VERSION ""

NS_ :

BS_:

BU_: CVC FZC RZC SC BCM ICU TCU Tester Plant_Sim

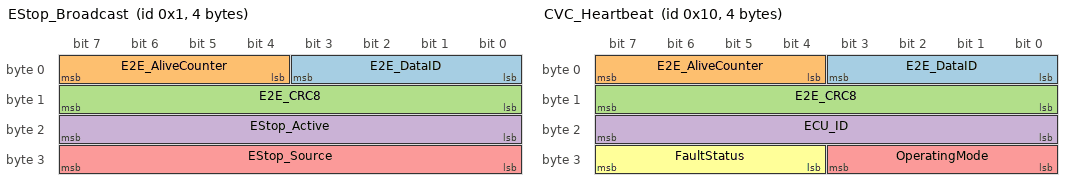
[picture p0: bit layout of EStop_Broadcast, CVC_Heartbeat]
BO_ 1 EStop_Broadcast: 4 CVC
 SG_ E2E_DataID : 0|4@1+ (1,0) [0|15] "" SC,FZC,RZC,BCM,ICU,TCU
 SG_ E2E_AliveCounter : 4|4@1+ (1,0) [0|15] "" SC,FZC,RZC,BCM,ICU,TCU
 SG_ E2E_CRC8 : 8|8@1+ (1,0) [0|255] "" SC,FZC,RZC,BCM,ICU,TCU
 SG_ EStop_Active : 16|8@1+ (1,0) [0|1] "" SC,FZC,RZC,BCM,ICU
 SG_ EStop_Source : 24|8@1+ (1,0) [0|7] "" SC,FZC,RZC,BCM,ICU

BO_ 16 CVC_Heartbeat: 4 CVC
 SG_ E2E_DataID : 0|4@1+ (1,0) [0|15] "" SC,FZC,RZC,ICU
 SG_ E2E_AliveCounter : 4|4@1+ (1,0) [0|15] "" SC,FZC,RZC,ICU
 SG_ E2E_CRC8 : 8|8@1+ (1,0) [0|255] "" SC,FZC,RZC,ICU
 SG_ ECU_ID : 16|8@1+ (1,0) [0|7] "" SC,FZC,RZC,ICU
 SG_ OperatingMode : 24|4@1+ (1,0) [0|5] "" SC,FZC,RZC,ICU
 SG_ FaultStatus : 28|4@1+ (1,0) [0|15] "" SC,FZC,RZC,ICU

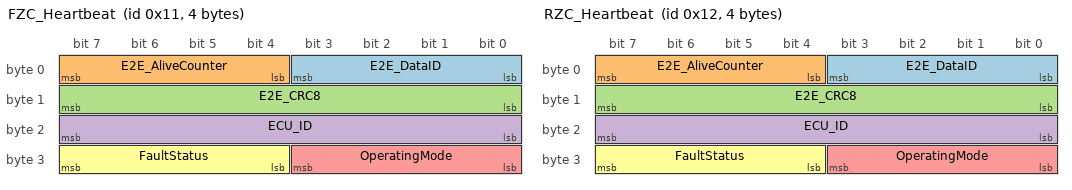
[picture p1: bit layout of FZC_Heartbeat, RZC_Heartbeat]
BO_ 17 FZC_Heartbeat: 4 FZC
 SG_ E2E_DataID : 0|4@1+ (1,0) [0|15] "" SC,CVC,ICU
 SG_ E2E_AliveCounter : 4|4@1+ (1,0) [0|15] "" SC,CVC,ICU
 SG_ E2E_CRC8 : 8|8@1+ (1,0) [0|255] "" SC,CVC,ICU
 SG_ ECU_ID : 16|8@1+ (1,0) [0|7] "" SC,CVC,ICU
 SG_ OperatingMode : 24|4@1+ (1,0) [0|5] "" SC,CVC,ICU
 SG_ FaultStatus : 28|4@1+ (1,0) [0|15] "" SC,CVC,ICU

BO_ 18 RZC_Heartbeat: 4 RZC
 SG_ E2E_DataID : 0|4@1+ (1,0) [0|15] "" SC,CVC,ICU
 SG_ E2E_AliveCounter : 4|4@1+ (1,0) [0|15] "" SC,CVC,ICU
 SG_ E2E_CRC8 : 8|8@1+ (1,0) [0|255] "" SC,CVC,ICU
 SG_ ECU_ID : 16|8@1+ (1,0) [0|7] "" SC,CVC,ICU
 SG_ OperatingMode : 24|4@1+ (1,0) [0|5] "" SC,CVC,ICU
 SG_ FaultStatus : 28|4@1+ (1,0) [0|15] "" SC,CVC,ICU

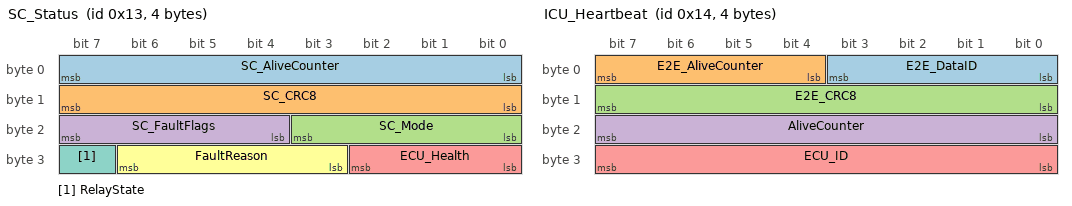
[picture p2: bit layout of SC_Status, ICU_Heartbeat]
BO_ 19 SC_Status: 4 SC
 SG_ SC_AliveCounter : 0|8@1+ (1,0) [0|255] "" CVC,FZC,RZC,ICU
 SG_ SC_CRC8 : 8|8@1+ (1,0) [0|255] "" CVC,FZC,RZC,ICU
 SG_ SC_Mode : 16|4@1+ (1,0) [0|3] "" CVC,FZC,RZC,ICU
 SG_ SC_FaultFlags : 20|4@1+ (1,0) [0|15] "" CVC,FZC,RZC,ICU
 SG_ ECU_Health : 24|3@1+ (1,0) [0|7] "" CVC,FZC,RZC,ICU
 SG_ FaultReason : 27|4@1+ (1,0) [0|15] "" CVC,FZC,RZC,ICU
 SG_ RelayState : 31|1@1+ (1,0) [0|1] "" CVC,FZC,RZC,ICU

BO_ 20 ICU_Heartbeat: 4 ICU
 SG_ E2E_DataID : 0|4@1+ (1,0) [0|15] "" CVC
 SG_ E2E_AliveCounter : 4|4@1+ (1,0) [0|15] "" CVC
 SG_ E2E_CRC8 : 8|8@1+ (1,0) [0|255] "" CVC
 SG_ AliveCounter : 16|8@1+ (1,0) [0|255] "" CVC
 SG_ ECU_ID : 24|8@1+ (1,0) [0|7] "" CVC

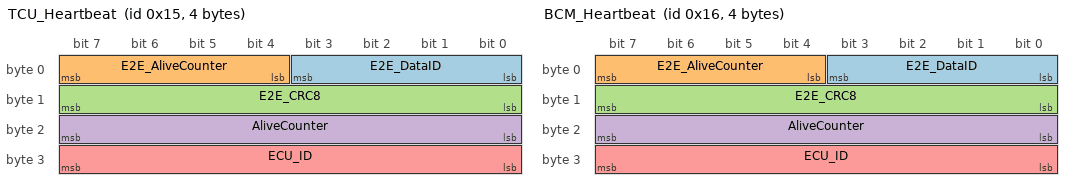
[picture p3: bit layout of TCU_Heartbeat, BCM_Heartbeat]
BO_ 21 TCU_Heartbeat: 4 TCU
 SG_ E2E_DataID : 0|4@1+ (1,0) [0|15] "" CVC
 SG_ E2E_AliveCounter : 4|4@1+ (1,0) [0|15] "" CVC
 SG_ E2E_CRC8 : 8|8@1+ (1,0) [0|255] "" CVC
 SG_ AliveCounter : 16|8@1+ (1,0) [0|255] "" CVC
 SG_ ECU_ID : 24|8@1+ (1,0) [0|7] "" CVC

BO_ 22 BCM_Heartbeat: 4 BCM
 SG_ E2E_DataID : 0|4@1+ (1,0) [0|15] "" CVC,ICU
 SG_ E2E_AliveCounter : 4|4@1+ (1,0) [0|15] "" CVC,ICU
 SG_ E2E_CRC8 : 8|8@1+ (1,0) [0|255] "" CVC,ICU
 SG_ AliveCounter : 16|8@1+ (1,0) [0|255] "" CVC,ICU
 SG_ ECU_ID : 24|8@1+ (1,0) [0|7] "" CVC,ICU

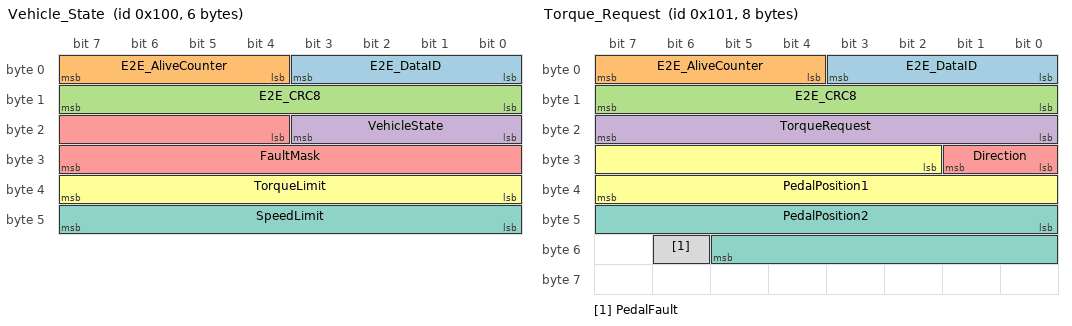
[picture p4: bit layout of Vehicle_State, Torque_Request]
BO_ 256 Vehicle_State: 6 CVC
 SG_ E2E_DataID : 0|4@1+ (1,0) [0|15] "" FZC,RZC,BCM,ICU,SC
 SG_ E2E_AliveCounter : 4|4@1+ (1,0) [0|15] "" FZC,RZC,BCM,ICU,SC
 SG_ E2E_CRC8 : 8|8@1+ (1,0) [0|255] "" FZC,RZC,BCM,ICU,SC
 SG_ VehicleState : 16|4@1+ (1,0) [0|5] "" FZC,RZC,BCM,ICU,SC
 SG_ FaultMask : 20|12@1+ (1,0) [0|4095] "" FZC,RZC,BCM,ICU,SC
 SG_ TorqueLimit : 32|8@1+ (1,0) [0|100] "%" RZC,ICU
 SG_ SpeedLimit : 40|8@1+ (1,0) [0|100] "%" RZC,ICU

BO_ 257 Torque_Request: 8 CVC
 SG_ E2E_DataID : 0|4@1+ (1,0) [0|15] "" RZC
 SG_ E2E_AliveCounter : 4|4@1+ (1,0) [0|15] "" RZC
 SG_ E2E_CRC8 : 8|8@1+ (1,0) [0|255] "" RZC
 SG_ TorqueRequest : 16|8@1+ (1,0) [0|100] "%" RZC
 SG_ Direction : 24|2@1+ (1,0) [0|2] "" RZC
 SG_ PedalPosition1 : 26|14@1+ (0.022,0) [0|359.98] "deg" RZC
 SG_ PedalPosition2 : 40|14@1+ (0.022,0) [0|359.98] "deg" RZC
 SG_ PedalFault : 54|1@1+ (1,0) [0|1] "" RZC

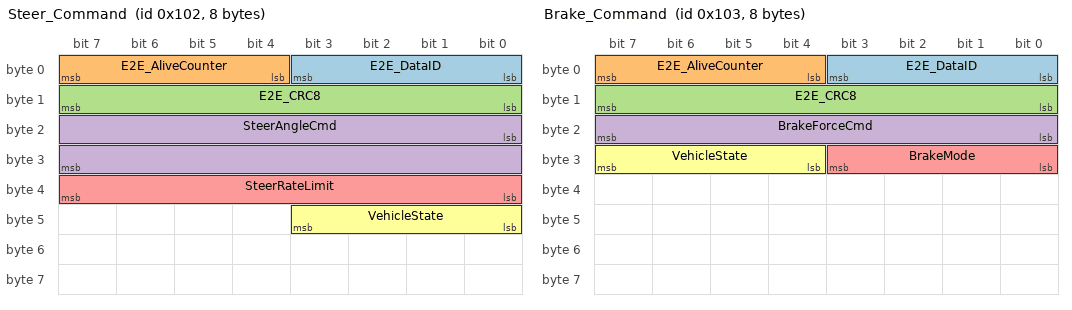
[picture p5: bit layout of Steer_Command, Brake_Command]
BO_ 258 Steer_Command: 8 CVC
 SG_ E2E_DataID : 0|4@1+ (1,0) [0|15] "" FZC
 SG_ E2E_AliveCounter : 4|4@1+ (1,0) [0|15] "" FZC
 SG_ E2E_CRC8 : 8|8@1+ (1,0) [0|255] "" FZC
 SG_ SteerAngleCmd : 16|16@1- (0.01,0) [-45.0|45.0] "deg" FZC
 SG_ SteerRateLimit : 32|8@1+ (0.2,0) [0|51.0] "deg/s" FZC
 SG_ VehicleState : 40|4@1+ (1,0) [0|5] "" FZC

BO_ 259 Brake_Command: 8 CVC
 SG_ E2E_DataID : 0|4@1+ (1,0) [0|15] "" FZC
 SG_ E2E_AliveCounter : 4|4@1+ (1,0) [0|15] "" FZC
 SG_ E2E_CRC8 : 8|8@1+ (1,0) [0|255] "" FZC
 SG_ BrakeForceCmd : 16|8@1+ (1,0) [0|100] "%" FZC
 SG_ BrakeMode : 24|4@1+ (1,0) [0|3] "" FZC
 SG_ VehicleState : 28|4@1+ (1,0) [0|5] "" FZC

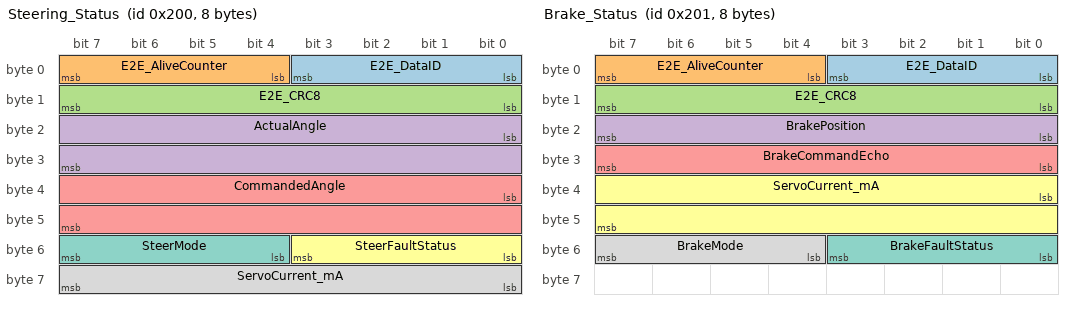
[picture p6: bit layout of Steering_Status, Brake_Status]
BO_ 512 Steering_Status: 8 FZC
 SG_ E2E_DataID : 0|4@1+ (1,0) [0|15] "" CVC,SC,ICU
 SG_ E2E_AliveCounter : 4|4@1+ (1,0) [0|15] "" CVC,SC,ICU
 SG_ E2E_CRC8 : 8|8@1+ (1,0) [0|255] "" CVC,SC,ICU
 SG_ ActualAngle : 16|16@1- (1,0) [-45|45] "deg" CVC,SC,ICU
 SG_ CommandedAngle : 32|16@1- (1,0) [-45|45] "deg" CVC,SC,ICU
 SG_ SteerFaultStatus : 48|4@1+ (1,0) [0|15] "" CVC,SC,ICU
 SG_ SteerMode : 52|4@1+ (1,0) [0|3] "" CVC,SC,ICU
 SG_ ServoCurrent_mA : 56|8@1+ (10,0) [0|2550] "mA" CVC,SC,ICU

BO_ 513 Brake_Status: 8 FZC
 SG_ E2E_DataID : 0|4@1+ (1,0) [0|15] "" CVC,SC,ICU
 SG_ E2E_AliveCounter : 4|4@1+ (1,0) [0|15] "" CVC,SC,ICU
 SG_ E2E_CRC8 : 8|8@1+ (1,0) [0|255] "" CVC,SC,ICU
 SG_ BrakePosition : 16|8@1+ (1,0) [0|100] "%" CVC,SC,ICU
 SG_ BrakeCommandEcho : 24|8@1+ (1,0) [0|100] "%" CVC,SC,ICU
 SG_ ServoCurrent_mA : 32|16@1+ (1,0) [0|3000] "mA" CVC,SC,ICU
 SG_ BrakeFaultStatus : 48|4@1+ (1,0) [0|15] "" CVC,SC,ICU
 SG_ BrakeMode : 52|4@1+ (1,0) [0|3] "" CVC,SC,ICU

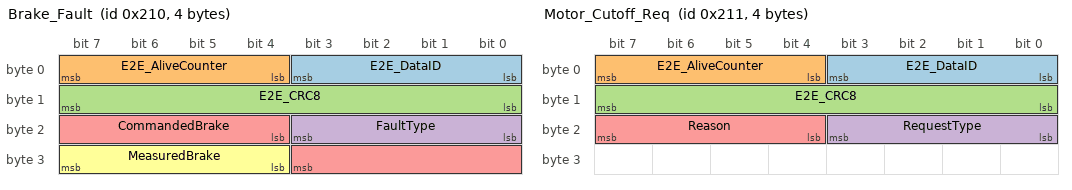
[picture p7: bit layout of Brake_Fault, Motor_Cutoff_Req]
BO_ 528 Brake_Fault: 4 FZC
 SG_ E2E_DataID : 0|4@1+ (1,0) [0|15] "" CVC,SC
 SG_ E2E_AliveCounter : 4|4@1+ (1,0) [0|15] "" CVC,SC
 SG_ E2E_CRC8 : 8|8@1+ (1,0) [0|255] "" CVC,SC
 SG_ FaultType : 16|4@1+ (1,0) [0|3] "" CVC,SC
 SG_ CommandedBrake : 20|8@1+ (1,0) [0|100] "%" CVC,SC
 SG_ MeasuredBrake : 28|4@1+ (10,0) [0|100] "%" CVC,SC

BO_ 529 Motor_Cutoff_Req: 4 FZC
 SG_ E2E_DataID : 0|4@1+ (1,0) [0|15] "" CVC
 SG_ E2E_AliveCounter : 4|4@1+ (1,0) [0|15] "" CVC
 SG_ E2E_CRC8 : 8|8@1+ (1,0) [0|255] "" CVC
 SG_ RequestType : 16|4@1+ (1,0) [0|3] "" CVC
 SG_ Reason : 20|4@1+ (1,0) [0|7] "" CVC

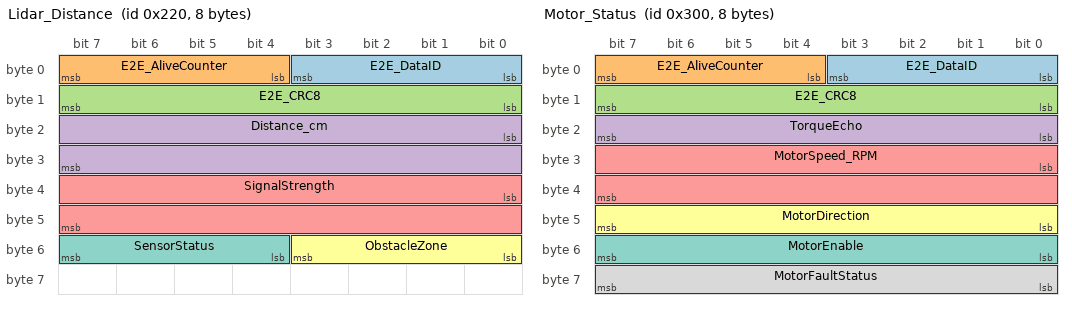
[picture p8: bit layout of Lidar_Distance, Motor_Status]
BO_ 544 Lidar_Distance: 8 FZC
 SG_ E2E_DataID : 0|4@1+ (1,0) [0|15] "" CVC,ICU
 SG_ E2E_AliveCounter : 4|4@1+ (1,0) [0|15] "" CVC,ICU
 SG_ E2E_CRC8 : 8|8@1+ (1,0) [0|255] "" CVC,ICU
 SG_ Distance_cm : 16|16@1+ (1,0) [0|1200] "cm" CVC,ICU
 SG_ SignalStrength : 32|16@1+ (1,0) [0|65535] "" CVC,ICU
 SG_ ObstacleZone : 48|4@1+ (1,0) [0|3] "" CVC,ICU
 SG_ SensorStatus : 52|4@1+ (1,0) [0|15] "" CVC,ICU

BO_ 768 Motor_Status: 8 RZC
 SG_ E2E_DataID : 0|4@1+ (1,0) [0|15] "" CVC,SC,ICU
 SG_ E2E_AliveCounter : 4|4@1+ (1,0) [0|15] "" CVC,SC,ICU
 SG_ E2E_CRC8 : 8|8@1+ (1,0) [0|255] "" CVC,SC,ICU
 SG_ TorqueEcho : 16|8@1+ (1,0) [0|100] "%" CVC,SC,ICU
 SG_ MotorSpeed_RPM : 24|16@1+ (1,0) [0|10000] "RPM" CVC,SC,ICU
 SG_ MotorDirection : 40|8@1+ (1,0) [0|2] "" CVC,SC,ICU
 SG_ MotorEnable : 48|8@1+ (1,0) [0|1] "" CVC,SC,ICU
 SG_ MotorFaultStatus : 56|8@1+ (1,0) [0|31] "" CVC,SC,ICU

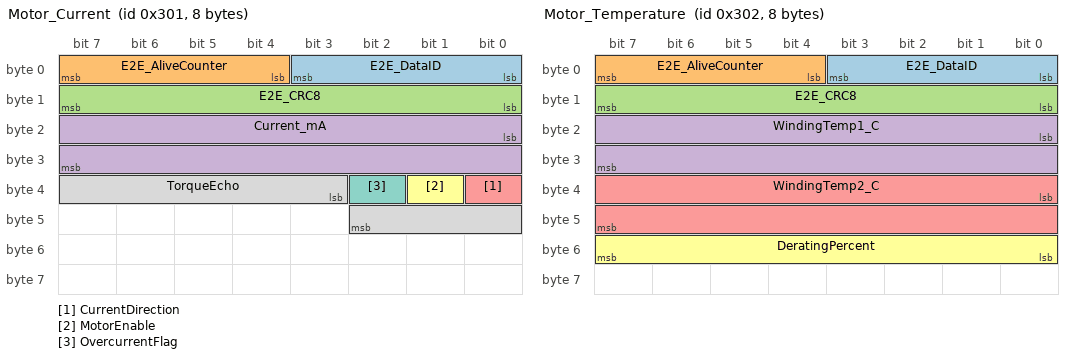
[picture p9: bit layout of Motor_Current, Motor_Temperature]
BO_ 769 Motor_Current: 8 RZC
 SG_ E2E_DataID : 0|4@1+ (1,0) [0|15] "" SC,CVC,ICU
 SG_ E2E_AliveCounter : 4|4@1+ (1,0) [0|15] "" SC,CVC,ICU
 SG_ E2E_CRC8 : 8|8@1+ (1,0) [0|255] "" SC,CVC,ICU
 SG_ Current_mA : 16|16@1+ (1,0) [0|30000] "mA" SC,CVC,ICU
 SG_ CurrentDirection : 32|1@1+ (1,0) [0|1] "" SC,CVC,ICU
 SG_ MotorEnable : 33|1@1+ (1,0) [0|1] "" SC,CVC,ICU
 SG_ OvercurrentFlag : 34|1@1+ (1,0) [0|1] "" SC,CVC,ICU
 SG_ TorqueEcho : 35|8@1+ (1,0) [0|100] "%" SC,CVC,ICU

BO_ 770 Motor_Temperature: 8 RZC
 SG_ E2E_DataID : 0|4@1+ (1,0) [0|15] "" CVC,ICU
 SG_ E2E_AliveCounter : 4|4@1+ (1,0) [0|15] "" CVC,ICU
 SG_ E2E_CRC8 : 8|8@1+ (1,0) [0|255] "" CVC,ICU
 SG_ WindingTemp1_C : 16|16@1+ (0.1,0) [0|200.0] "degC" CVC,ICU
 SG_ WindingTemp2_C : 32|16@1+ (0.1,0) [0|200.0] "degC" CVC,ICU
 SG_ DeratingPercent : 48|8@1+ (1,0) [0|100] "%" CVC,ICU

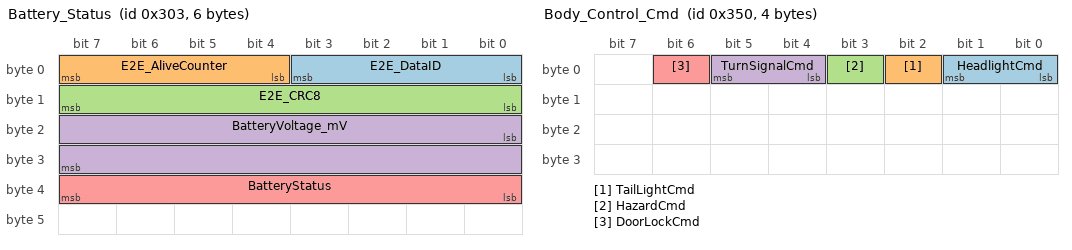
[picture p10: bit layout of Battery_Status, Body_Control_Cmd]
BO_ 771 Battery_Status: 6 RZC
 SG_ E2E_DataID : 0|4@1+ (1,0) [0|15] "" CVC,ICU
 SG_ E2E_AliveCounter : 4|4@1+ (1,0) [0|15] "" CVC,ICU
 SG_ E2E_CRC8 : 8|8@1+ (1,0) [0|255] "" CVC,ICU
 SG_ BatteryVoltage_mV : 16|16@1+ (1,0) [0|20000] "mV" CVC,ICU
 SG_ BatteryStatus : 32|8@1+ (1,0) [0|4] "" CVC,ICU

BO_ 848 Body_Control_Cmd: 4 CVC
 SG_ HeadlightCmd : 0|2@1+ (1,0) [0|2] "" BCM
 SG_ TailLightCmd : 2|1@1+ (1,0) [0|1] "" BCM
 SG_ HazardCmd : 3|1@1+ (1,0) [0|1] "" BCM
 SG_ TurnSignalCmd : 4|2@1+ (1,0) [0|2] "" BCM
 SG_ DoorLockCmd : 6|1@1+ (1,0) [0|1] "" BCM

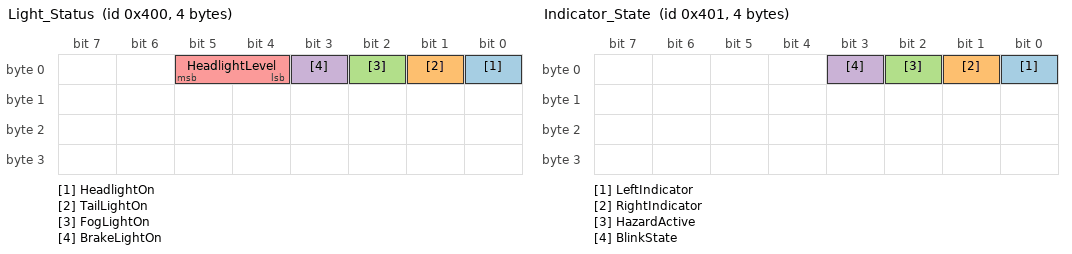
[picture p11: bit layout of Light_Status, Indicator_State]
BO_ 1024 Light_Status: 4 BCM
 SG_ HeadlightOn : 0|1@1+ (1,0) [0|1] "" ICU
 SG_ TailLightOn : 1|1@1+ (1,0) [0|1] "" ICU
 SG_ FogLightOn : 2|1@1+ (1,0) [0|1] "" ICU
 SG_ BrakeLightOn : 3|1@1+ (1,0) [0|1] "" ICU
 SG_ HeadlightLevel : 4|2@1+ (1,0) [0|2] "" ICU

BO_ 1025 Indicator_State: 4 BCM
 SG_ LeftIndicator : 0|1@1+ (1,0) [0|1] "" ICU
 SG_ RightIndicator : 1|1@1+ (1,0) [0|1] "" ICU
 SG_ HazardActive : 2|1@1+ (1,0) [0|1] "" ICU
 SG_ BlinkState : 3|1@1+ (1,0) [0|1] "" ICU

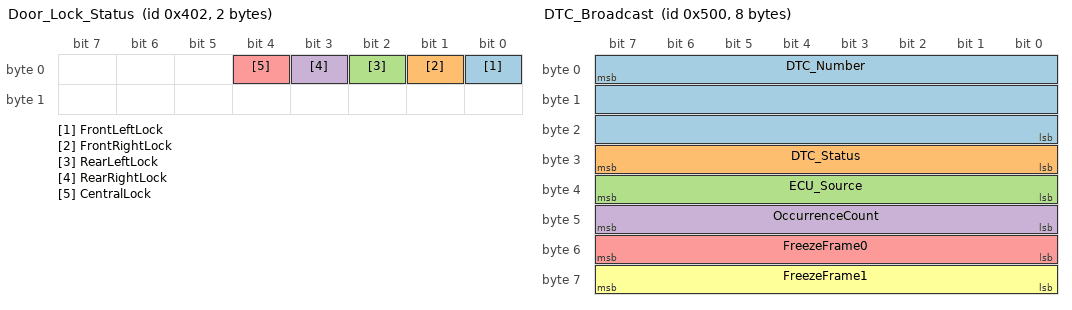
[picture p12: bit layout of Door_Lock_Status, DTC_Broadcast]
BO_ 1026 Door_Lock_Status: 2 BCM
 SG_ FrontLeftLock : 0|1@1+ (1,0) [0|1] "" ICU
 SG_ FrontRightLock : 1|1@1+ (1,0) [0|1] "" ICU
 SG_ RearLeftLock : 2|1@1+ (1,0) [0|1] "" ICU
 SG_ RearRightLock : 3|1@1+ (1,0) [0|1] "" ICU
 SG_ CentralLock : 4|1@1+ (1,0) [0|1] "" ICU

BO_ 1280 DTC_Broadcast: 8 CVC
 SG_ DTC_Number : 7|24@0+ (1,0) [0|16777215] "" TCU,ICU
 SG_ DTC_Status : 24|8@1+ (1,0) [0|255] "" TCU,ICU
 SG_ ECU_Source : 32|8@1+ (1,0) [0|7] "" TCU,ICU
 SG_ OccurrenceCount : 40|8@1+ (1,0) [0|255] "" TCU,ICU
 SG_ FreezeFrame0 : 48|8@1+ (1,0) [0|255] "" TCU,ICU
 SG_ FreezeFrame1 : 56|8@1+ (1,0) [0|255] "" TCU,ICU

BO_ 2015 UDS_Func_Request: 8 Tester
 SG_ UDS_Data : 0|64@1+ (1,0) [0|0] "" CVC,FZC,RZC,TCU,BCM,ICU

BO_ 2016 UDS_Phys_Req_CVC: 8 Tester
 SG_ UDS_Data : 0|64@1+ (1,0) [0|0] "" CVC

BO_ 2017 UDS_Phys_Req_FZC: 8 Tester
 SG_ UDS_Data : 0|64@1+ (1,0) [0|0] "" FZC

BO_ 2018 UDS_Phys_Req_RZC: 8 Tester
 SG_ UDS_Data : 0|64@1+ (1,0) [0|0] "" RZC

BO_ 2019 UDS_Phys_Req_TCU: 8 Tester
 SG_ UDS_Data : 0|64@1+ (1,0) [0|0] "" TCU

BO_ 2024 UDS_Resp_CVC: 8 CVC
 SG_ UDS_Data : 0|64@1+ (1,0) [0|0] "" Tester

BO_ 2025 UDS_Resp_FZC: 8 FZC
 SG_ UDS_Data : 0|64@1+ (1,0) [0|0] "" Tester

BO_ 2026 UDS_Resp_RZC: 8 RZC
 SG_ UDS_Data : 0|64@1+ (1,0) [0|0] "" Tester

BO_ 1604 UDS_Resp_TCU: 8 TCU
 SG_ UDS_Data : 0|64@1+ (1,0) [0|0] "" Tester

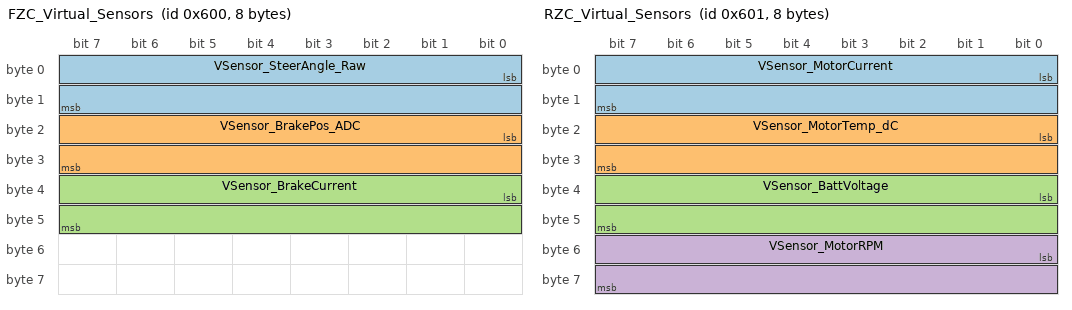
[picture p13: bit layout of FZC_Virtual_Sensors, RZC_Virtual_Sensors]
BO_ 1536 FZC_Virtual_Sensors: 8 Plant_Sim
 SG_ VSensor_SteerAngle_Raw : 0|16@1+ (1,0) [0|16383] "" FZC
 SG_ VSensor_BrakePos_ADC : 16|16@1+ (1,0) [0|1000] "" FZC
 SG_ VSensor_BrakeCurrent : 32|16@1+ (1,0) [0|65535] "mA" FZC

BO_ 1537 RZC_Virtual_Sensors: 8 Plant_Sim
 SG_ VSensor_MotorCurrent : 0|16@1+ (1,0) [0|65535] "mA" RZC
 SG_ VSensor_MotorTemp_dC : 16|16@1+ (1,0) [0|2000] "" RZC
 SG_ VSensor_BattVoltage : 32|16@1+ (1,0) [0|20000] "mV" RZC
 SG_ VSensor_MotorRPM : 48|16@1+ (1,0) [0|10000] "rpm" RZC

CM_ BO_ 1536 "Plant-sim virtual sensors for FZC. SIL/HIL only. 10ms periodic. No E2E.";
CM_ BO_ 1537 "Plant-sim virtual sensors for RZC. SIL/HIL only. 10ms periodic. No E2E.";

CM_ BU_ CVC "Central Vehicle Computer -- STM32F446RE, ASIL D";
CM_ BU_ FZC "Front Zone Controller -- STM32F446RE, ASIL D";
CM_ BU_ RZC "Rear Zone Controller -- STM32F446RE, ASIL C";
CM_ BU_ SC "Safety Controller -- TMS570LS0432, ASIL D";
CM_ BU_ BCM "Body Control Module -- Docker simulated, QM";
CM_ BU_ ICU "Instrument Cluster Unit -- Docker simulated, QM";
CM_ BU_ TCU "Telematics Control Unit -- Docker simulated, QM";

CM_ BO_ 1 "Emergency stop broadcast. Event-triggered, 10ms repeat while active.";
CM_ BO_ 16 "CVC heartbeat. 50ms periodic. SC monitors for timeout.";
CM_ BO_ 17 "FZC heartbeat. 50ms periodic. SC monitors for timeout.";
CM_ BO_ 18 "RZC heartbeat. 50ms periodic. SC monitors for timeout.";
CM_ BO_ 19 "SC status broadcast. 500ms periodic. Simplified E2E (8-bit counter + CRC-8).";
CM_ BO_ 20 "ICU heartbeat. 500ms periodic. QM.";
CM_ BO_ 21 "TCU heartbeat. 500ms periodic. QM.";
CM_ BO_ 256 "Vehicle state broadcast. 10ms periodic. Contains state machine and torque/speed limits.";
CM_ BO_ 257 "Torque request from CVC to RZC. 10ms periodic. ASIL D.";
CM_ BO_ 258 "Steering command from CVC to FZC. 10ms periodic. ASIL D.";
CM_ BO_ 259 "Brake command from CVC to FZC. 10ms periodic. ASIL D.";
CM_ BO_ 512 "Steering status feedback from FZC. 20ms periodic.";
CM_ BO_ 513 "Brake status feedback from FZC. 20ms periodic.";
CM_ BO_ 528 "Brake fault event from FZC. ASIL D.";
CM_ BO_ 529 "Motor cutoff request from FZC to CVC. Event, 10ms repeat.";
CM_ BO_ 544 "Lidar distance from FZC. 10ms periodic. TFMini-S sensor.";
CM_ BO_ 768 "Motor status from RZC. 20ms periodic. Encoder speed + faults.";
CM_ BO_ 769 "Motor current from RZC. 10ms periodic. ACS723 sensor.";
CM_ BO_ 770 "Motor temperature from RZC. 100ms periodic. NTC thermistor.";
CM_ BO_ 771 "Battery status from RZC. 1000ms periodic. No E2E.";
CM_ BO_ 848 "Body control command from CVC to BCM. 100ms periodic.";
CM_ BO_ 1024 "Light status from BCM. 100ms periodic.";
CM_ BO_ 1025 "Indicator state from BCM. 100ms periodic.";
CM_ BO_ 1026 "Door lock status from BCM. Event-triggered.";
CM_ BO_ 1280 "DTC broadcast. Event-triggered. Any ECU can send.";

VAL_ 1 EStop_Source 0 "CVC_button" 1 "CAN_request" 2 "SC_relay" ;
VAL_ 16 OperatingMode 0 "INIT" 1 "RUN" 2 "DEGRADED" 3 "LIMP" 4 "SAFE_STOP" 5 "SHUTDOWN" ;
VAL_ 17 OperatingMode 0 "INIT" 1 "RUN" 2 "DEGRADED" 3 "LIMP" 4 "SAFE_STOP" 5 "SHUTDOWN" ;
VAL_ 18 OperatingMode 0 "INIT" 1 "RUN" 2 "DEGRADED" 3 "LIMP" 4 "SAFE_STOP" 5 "SHUTDOWN" ;
VAL_ 19 SC_Mode 0 "INIT" 1 "MONITORING" 2 "FAULT_DETECTED" 3 "SAFE_STOP" ;
VAL_ 256 VehicleState 0 "INIT" 1 "RUN" 2 "DEGRADED" 3 "LIMP" 4 "SAFE_STOP" 5 "SHUTDOWN" ;
VAL_ 257 Direction 0 "stopped" 1 "forward" 2 "reverse" ;
VAL_ 259 BrakeMode 0 "release" 1 "normal" 2 "emergency" 3 "auto" ;
VAL_ 512 SteerMode 0 "normal" 1 "return_center" 2 "disabled" 3 "local" ;
VAL_ 513 BrakeMode 0 "release" 1 "normal" 2 "auto_brake" 3 "emergency" ;
VAL_ 528 FaultType 0 "PWM_mismatch" 1 "servo_stuck" 2 "overcurrent" 3 "timeout" ;
VAL_ 529 RequestType 0 "motor_cutoff" 1 "speed_reduce" 2 "e_stop_fwd" ;
VAL_ 529 Reason 0 "brake_fault" 1 "steer_fault" 2 "lidar_emergency" 3 "CAN_loss" ;
VAL_ 544 ObstacleZone 0 "emergency" 1 "braking" 2 "warning" 3 "clear" ;
VAL_ 768 MotorDirection 0 "stopped" 1 "forward" 2 "reverse" ;
VAL_ 769 CurrentDirection 0 "forward" 1 "reverse" ;
VAL_ 771 BatteryStatus 0 "critical_UV" 1 "UV_warn" 2 "normal" 3 "OV_warn" 4 "critical_OV" ;
VAL_ 848 HeadlightCmd 0 "off" 1 "low" 2 "high" ;
VAL_ 848 TurnSignalCmd 0 "off" 1 "left" 2 "right" ;
VAL_ 1024 HeadlightLevel 0 "off" 1 "low" 2 "high" ;
VAL_ 1280 ECU_Source 1 "CVC" 2 "FZC" 3 "RZC" 4 "SC" 5 "BCM" 6 "ICU" 7 "TCU" ;

BA_DEF_ BO_ "GenMsgCycleTime" INT 0 10000;
BA_DEF_ BO_ "GenMsgSendType" STRING;
BA_DEF_ BO_ "ASIL" STRING;
BA_DEF_ BO_ "E2E_DataID" INT -1 255;

BA_ "GenMsgCycleTime" BO_ 1 10;
BA_ "GenMsgCycleTime" BO_ 16 50;
BA_ "GenMsgCycleTime" BO_ 17 50;
BA_ "GenMsgCycleTime" BO_ 18 50;
BA_ "GenMsgCycleTime" BO_ 19 500;
BA_ "GenMsgCycleTime" BO_ 20 500;
BA_ "GenMsgCycleTime" BO_ 21 500;
BA_ "GenMsgCycleTime" BO_ 256 10;
BA_ "GenMsgCycleTime" BO_ 257 10;
BA_ "GenMsgCycleTime" BO_ 258 10;
BA_ "GenMsgCycleTime" BO_ 259 10;
BA_ "GenMsgCycleTime" BO_ 512 20;
BA_ "GenMsgCycleTime" BO_ 513 20;
BA_ "GenMsgCycleTime" BO_ 528 0;
BA_ "GenMsgCycleTime" BO_ 529 10;
BA_ "GenMsgCycleTime" BO_ 544 10;
BA_ "GenMsgCycleTime" BO_ 768 20;
BA_ "GenMsgCycleTime" BO_ 769 10;
BA_ "GenMsgCycleTime" BO_ 770 100;
BA_ "GenMsgCycleTime" BO_ 771 1000;
BA_ "GenMsgCycleTime" BO_ 848 100;
BA_ "GenMsgCycleTime" BO_ 1024 100;
BA_ "GenMsgCycleTime" BO_ 1025 100;
BA_ "GenMsgCycleTime" BO_ 1026 0;
BA_ "GenMsgCycleTime" BO_ 1280 0;

BA_ "GenMsgSendType" BO_ 1 "event";
BA_ "GenMsgSendType" BO_ 16 "cyclic";
BA_ "GenMsgSendType" BO_ 17 "cyclic";
BA_ "GenMsgSendType" BO_ 18 "cyclic";
BA_ "GenMsgSendType" BO_ 19 "cyclic";
BA_ "GenMsgSendType" BO_ 20 "cyclic";
BA_ "GenMsgSendType" BO_ 21 "cyclic";
BA_ "GenMsgSendType" BO_ 256 "cyclic";
BA_ "GenMsgSendType" BO_ 257 "cyclic";
BA_ "GenMsgSendType" BO_ 258 "cyclic";
BA_ "GenMsgSendType" BO_ 259 "cyclic";
BA_ "GenMsgSendType" BO_ 512 "cyclic";
BA_ "GenMsgSendType" BO_ 513 "cyclic";
BA_ "GenMsgSendType" BO_ 528 "event";
BA_ "GenMsgSendType" BO_ 529 "event";
BA_ "GenMsgSendType" BO_ 544 "cyclic";
BA_ "GenMsgSendType" BO_ 768 "cyclic";
BA_ "GenMsgSendType" BO_ 769 "cyclic";
BA_ "GenMsgSendType" BO_ 770 "cyclic";
BA_ "GenMsgSendType" BO_ 771 "cyclic";
BA_ "GenMsgSendType" BO_ 848 "cyclic";
BA_ "GenMsgSendType" BO_ 1024 "cyclic";
BA_ "GenMsgSendType" BO_ 1025 "cyclic";
BA_ "GenMsgSendType" BO_ 1026 "event";
BA_ "GenMsgSendType" BO_ 1280 "event";

BA_ "ASIL" BO_ 1 "B";
BA_ "ASIL" BO_ 16 "C";
BA_ "ASIL" BO_ 17 "C";
BA_ "ASIL" BO_ 18 "C";
BA_ "ASIL" BO_ 19 "D";
BA_ "ASIL" BO_ 20 "QM";
BA_ "ASIL" BO_ 21 "QM";
BA_ "ASIL" BO_ 256 "D";
BA_ "ASIL" BO_ 257 "D";
BA_ "ASIL" BO_ 258 "D";
BA_ "ASIL" BO_ 259 "D";
BA_ "ASIL" BO_ 512 "D";
BA_ "ASIL" BO_ 513 "D";
BA_ "ASIL" BO_ 528 "D";
BA_ "ASIL" BO_ 529 "D";
BA_ "ASIL" BO_ 544 "C";
BA_ "ASIL" BO_ 768 "D";
BA_ "ASIL" BO_ 769 "C";
BA_ "ASIL" BO_ 770 "A";
BA_ "ASIL" BO_ 771 "QM";
BA_ "ASIL" BO_ 848 "QM";
BA_ "ASIL" BO_ 1024 "QM";
BA_ "ASIL" BO_ 1025 "QM";
BA_ "ASIL" BO_ 1026 "QM";
BA_ "ASIL" BO_ 1280 "QM";

BA_ "E2E_DataID" BO_ 1 1;
BA_ "E2E_DataID" BO_ 16 2;
BA_ "E2E_DataID" BO_ 17 3;
BA_ "E2E_DataID" BO_ 18 4;
BA_ "E2E_DataID" BO_ 256 5;
BA_ "E2E_DataID" BO_ 257 6;
BA_ "E2E_DataID" BO_ 258 7;
BA_ "E2E_DataID" BO_ 259 8;
BA_ "E2E_DataID" BO_ 512 9;
BA_ "E2E_DataID" BO_ 513 10;
BA_ "E2E_DataID" BO_ 528 11;
BA_ "E2E_DataID" BO_ 529 12;
BA_ "E2E_DataID" BO_ 544 13;
BA_ "E2E_DataID" BO_ 768 14;
BA_ "E2E_DataID" BO_ 769 15;
BA_ "E2E_DataID" BO_ 770 0;
BA_ "E2E_DataID" BO_ 20 16;
BA_ "E2E_DataID" BO_ 21 17;
BA_ "E2E_DataID" BO_ 22 18;
BA_ "E2E_DataID" BO_ 771 19;
